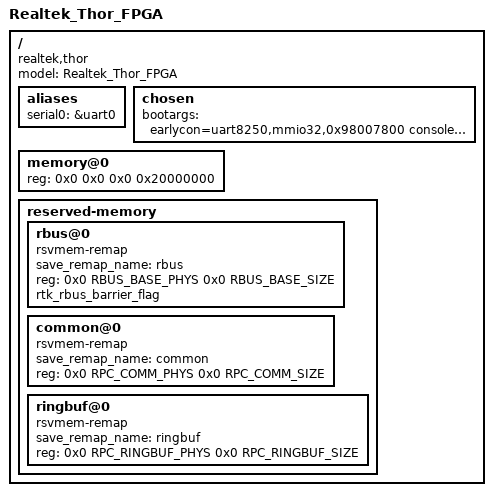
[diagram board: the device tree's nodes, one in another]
/dts-v1/;
#include <dt-bindings/soc/rtd16xx,memory.h>

/* 0x00000000 ~ 0x0002ffff */
/memreserve/ SYS_BOOTCODE_MEMBASE SYS_BOOTCODE_MEMSIZE;
/* 0x0001f000 ~ 0x0001ffff */
/memreserve/ RPC_COMM_PHYS RPC_COMM_SIZE;
/* 0x01ffe000 ~ 0x02001fff */
/memreserve/ RPC_RINGBUF_PHYS RPC_RINGBUF_SIZE;

#include "thor-fpga.dtsi"

/ {
	model= "Realtek_Thor_FPGA";
	compatible =  "realtek,thor";

	aliases {
		serial0 = &uart0;
	};

	chosen {
		bootargs = "earlycon=uart8250,mmio32,0x98007800 console=ttyS0,115200 init=/init loglevel=7";
	};

	memory@0 {
		device_type = "memory";
		reg = <0x0 0x0 0x0 0x20000000>;	/* 512 MB */
	};
	
	reserved-memory {
		#address-cells = <2>;
		#size-cells = <2>;
		ranges;

		rbus@0 {
			compatible = "rsvmem-remap";
			save_remap_name = "rbus";
			reg = <0x0 RBUS_BASE_PHYS 0x0 RBUS_BASE_SIZE>;
			rtk_rbus_barrier_flag;
		};

		common@0 {
			compatible = "rsvmem-remap";
			save_remap_name = "common";
			reg = <0x0 RPC_COMM_PHYS 0x0 RPC_COMM_SIZE>;
		};

		ringbuf@0 {
			compatible = "rsvmem-remap";
			save_remap_name = "ringbuf";
			reg = <0x0 RPC_RINGBUF_PHYS 0x0 RPC_RINGBUF_SIZE>;
		};
	};
};
